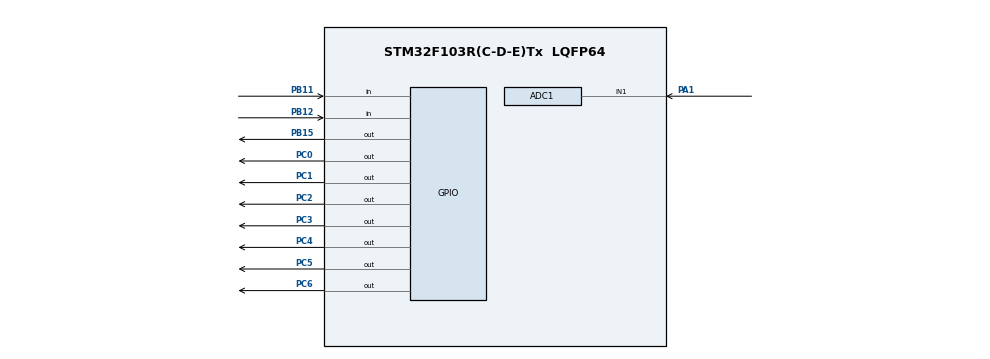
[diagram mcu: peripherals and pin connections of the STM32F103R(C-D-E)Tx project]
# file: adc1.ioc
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ADC1.Channel-0\#ChannelRegularConversion=ADC_CHANNEL_1
ADC1.NbrOfConversionFlag=1
ADC1.Rank-0\#ChannelRegularConversion=1
ADC1.SamplingTime-0\#ChannelRegularConversion=ADC_SAMPLETIME_1CYCLE_5
ADC1.master=1
Mcu.Family=STM32F1
Mcu.Name=STM32F103R(C-D-E)Tx
Mcu.Package=LQFP64
NVIC.PriorityGroup=NVIC_PRIORITYGROUP_4
PA1.Signal=ADCx_IN1
PA13.Mode=Serial_Wire
PA13.Signal=SYS_JTMS-SWDIO
PA14.Mode=Serial_Wire
PA14.Signal=SYS_JTCK-SWCLK
PB11.Signal=GPIO_Input
PB12.Signal=GPIO_Input
PB15.Signal=GPIO_Output
PC0.Signal=GPIO_Output
PC1.Signal=GPIO_Output
PC2.Signal=GPIO_Output
PC3.Signal=GPIO_Output
PC4.Signal=GPIO_Output
PC5.Signal=GPIO_Output
PC6.Signal=GPIO_Output
ProjectManager.HeapSize=0x200
ProjectManager.StackSize=0x400
ProjectManager.TargetToolchain=EWARM V8
RCC.APB1Freq_Value=8000000
RCC.APB2Freq_Value=8000000
SH.ADCx_IN1.0=ADC1_IN1,IN1
board=custom

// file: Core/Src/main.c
/* USER CODE BEGIN Header */
/**
  ******************************************************************************
  * @file           : main.c
  * @brief          : Main program body
  ******************************************************************************
  * @attention
  *
  * Copyright (c) 2024 STMicroelectronics.
  * All rights reserved.
  *
  * This software is licensed under terms that can be found in the LICENSE file
  * in the root directory of this software component.
  * If no LICENSE file comes with this software, it is provided AS-IS.
  *
  ******************************************************************************
  */
/* USER CODE END Header */
#include "main.h"

/* USER CODE BEGIN Includes */
#include "LCD/lcd.h"
#include <stdio.h>
/* USER CODE END Includes */

ADC_HandleTypeDef hadc1;

/* USER CODE BEGIN PV */
char str [16];
float val;
/* USER CODE END PV */

void SystemClock_Config(void);
static void MX_GPIO_Init(void);
static void MX_ADC1_Init(void);

int main(void)
{

  /* MCU Configuration--------------------------------------------------------*/

  /* Reset of all peripherals, Initializes the Flash interface and the Systick. */
  HAL_Init();

  /* Configure the system clock */
  SystemClock_Config();

  /* Initialize all configured peripherals */
  MX_GPIO_Init();
  MX_ADC1_Init();
  /* USER CODE BEGIN 2 */
  lcd_init();
  lcd_clear();
  lcd_puts("ADC");
  HAL_Delay(2000);
  lcd_clear();
  HAL_ADC_Init(&hadc1);

  /* USER CODE END 2 */

  /* Infinite loop */
  while (1)
  {

     HAL_ADC_Start(&hadc1);
  if (HAL_ADC_PollForConversion(&hadc1, 1000) == HAL_OK) {
    val = HAL_ADC_GetValue(&hadc1);
    sprintf(str, "value is : %4.2f", val); // Updated format specifier
    lcd_gotoxy(0, 0);
    lcd_puts(str);
    HAL_Delay(1000); // Delay to allow reading the display
  } else {
    lcd_gotoxy(0, 0);
    lcd_puts("ADC Error"); // Display error if ADC conversion fails
  }
  }
}

void SystemClock_Config(void)
{
  RCC_OscInitTypeDef RCC_OscInitStruct = {0};
  RCC_ClkInitTypeDef RCC_ClkInitStruct = {0};
  RCC_PeriphCLKInitTypeDef PeriphClkInit = {0};

  /** Initializes the RCC Oscillators according to the specified parameters
  * in the RCC_OscInitTypeDef structure.
  */
  RCC_OscInitStruct.OscillatorType = RCC_OSCILLATORTYPE_HSI;
  RCC_OscInitStruct.HSIState = RCC_HSI_ON;
  RCC_OscInitStruct.HSICalibrationValue = RCC_HSICALIBRATION_DEFAULT;
  RCC_OscInitStruct.PLL.PLLState = RCC_PLL_NONE;
  if (HAL_RCC_OscConfig(&RCC_OscInitStruct) != HAL_OK)
  {
    Error_Handler();
  }

  /** Initializes the CPU, AHB and APB buses clocks
  */
  RCC_ClkInitStruct.ClockType = RCC_CLOCKTYPE_HCLK|RCC_CLOCKTYPE_SYSCLK
                              |RCC_CLOCKTYPE_PCLK1|RCC_CLOCKTYPE_PCLK2;
  RCC_ClkInitStruct.SYSCLKSource = RCC_SYSCLKSOURCE_HSI;
  RCC_ClkInitStruct.AHBCLKDivider = RCC_SYSCLK_DIV1;
  RCC_ClkInitStruct.APB1CLKDivider = RCC_HCLK_DIV1;
  RCC_ClkInitStruct.APB2CLKDivider = RCC_HCLK_DIV1;

  if (HAL_RCC_ClockConfig(&RCC_ClkInitStruct, FLASH_LATENCY_0) != HAL_OK)
  {
    Error_Handler();
  }
  PeriphClkInit.PeriphClockSelection = RCC_PERIPHCLK_ADC;
  PeriphClkInit.AdcClockSelection = RCC_ADCPCLK2_DIV2;
  if (HAL_RCCEx_PeriphCLKConfig(&PeriphClkInit) != HAL_OK)
  {
    Error_Handler();
  }
}

static void MX_ADC1_Init(void)
{

  ADC_ChannelConfTypeDef sConfig = {0};

  /** Common config
  */
  hadc1.Instance = ADC1;
  hadc1.Init.ScanConvMode = ADC_SCAN_DISABLE;
  hadc1.Init.ContinuousConvMode = DISABLE;
  hadc1.Init.DiscontinuousConvMode = DISABLE;
  hadc1.Init.ExternalTrigConv = ADC_SOFTWARE_START;
  hadc1.Init.DataAlign = ADC_DATAALIGN_RIGHT;
  hadc1.Init.NbrOfConversion = 1;
  if (HAL_ADC_Init(&hadc1) != HAL_OK)
  {
    Error_Handler();
  }

  /** Configure Regular Channel
  */
  sConfig.Channel = ADC_CHANNEL_1;
  sConfig.Rank = ADC_REGULAR_RANK_1;
  sConfig.SamplingTime = ADC_SAMPLETIME_1CYCLE_5;
  if (HAL_ADC_ConfigChannel(&hadc1, &sConfig) != HAL_OK)
  {
    Error_Handler();
  }

}

static void MX_GPIO_Init(void)
{
  GPIO_InitTypeDef GPIO_InitStruct = {0};

  /* GPIO Ports Clock Enable */
  __HAL_RCC_GPIOC_CLK_ENABLE();
  __HAL_RCC_GPIOA_CLK_ENABLE();
  __HAL_RCC_GPIOB_CLK_ENABLE();

  /*Configure GPIO pin Output Level */
  HAL_GPIO_WritePin(GPIOC, GPIO_PIN_0|GPIO_PIN_1|GPIO_PIN_2|GPIO_PIN_3
                          |GPIO_PIN_4|GPIO_PIN_5|GPIO_PIN_6, GPIO_PIN_RESET);

  /*Configure GPIO pin Output Level */
  HAL_GPIO_WritePin(GPIOB, GPIO_PIN_15, GPIO_PIN_RESET);

  /*Configure GPIO pins : PC0 PC1 PC2 PC3
                           PC4 PC5 PC6 */
  GPIO_InitStruct.Pin = GPIO_PIN_0|GPIO_PIN_1|GPIO_PIN_2|GPIO_PIN_3
                          |GPIO_PIN_4|GPIO_PIN_5|GPIO_PIN_6;
  GPIO_InitStruct.Mode = GPIO_MODE_OUTPUT_PP;
  GPIO_InitStruct.Pull = GPIO_NOPULL;
  GPIO_InitStruct.Speed = GPIO_SPEED_FREQ_LOW;
  HAL_GPIO_Init(GPIOC, &GPIO_InitStruct);

  /*Configure GPIO pins : PB11 PB12 */
  GPIO_InitStruct.Pin = GPIO_PIN_11|GPIO_PIN_12;
  GPIO_InitStruct.Mode = GPIO_MODE_INPUT;
  GPIO_InitStruct.Pull = GPIO_NOPULL;
  HAL_GPIO_Init(GPIOB, &GPIO_InitStruct);

  /*Configure GPIO pin : PB15 */
  GPIO_InitStruct.Pin = GPIO_PIN_15;
  GPIO_InitStruct.Mode = GPIO_MODE_OUTPUT_PP;
  GPIO_InitStruct.Pull = GPIO_NOPULL;
  GPIO_InitStruct.Speed = GPIO_SPEED_FREQ_LOW;
  HAL_GPIO_Init(GPIOB, &GPIO_InitStruct);

}

void Error_Handler(void)
{
  __disable_irq();
  while (1)
  {
  }
}
